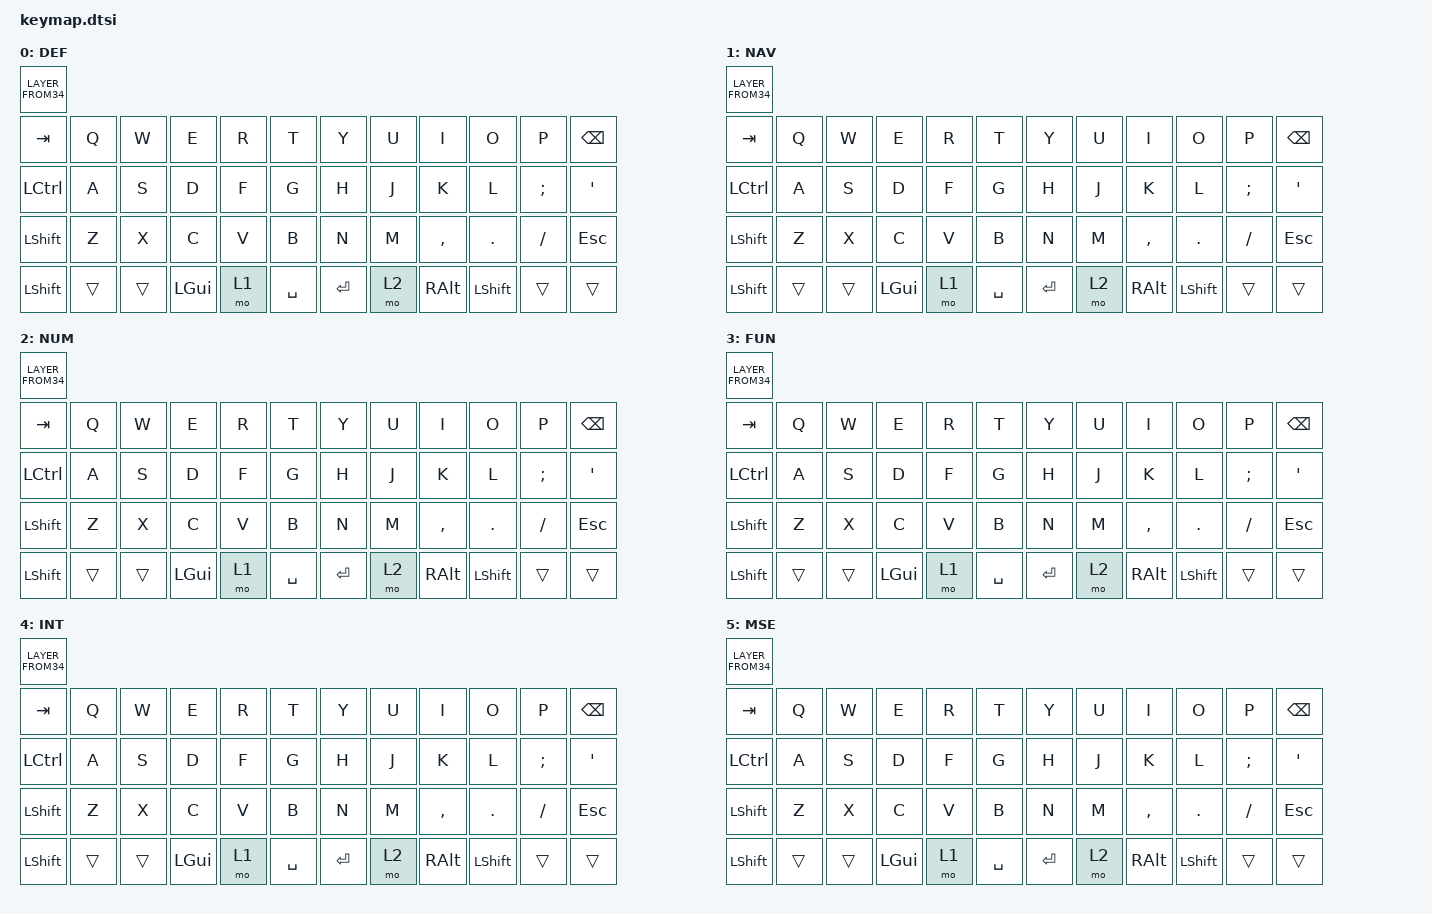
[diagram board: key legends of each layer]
/*
 * Copyright (c) 2020 The ZMK Contributors
 *
 * SPDX-License-Identifier: MIT
 */

#include <dt-bindings/zmk/bt.h>
#include <dt-bindings/zmk/keys.h>
#include <dt-bindings/zmk/mouse.h>
#include <dt-bindings/zmk/outputs.h>

#ifndef KEYMAP_DRAWER
#include "include/keys_de.h"
#endif

#define DEF 0
#define NAV 1
#define NUM 2
#define FUN 3
#define INT 4
#define MSE 5

#define CT(KEY) &mt LC(KEY) KEY

#define MEH     LC(LS(LALT))
#define HYPER   LC(LS(LA(LGUI)))

#define U_RDO   LC(DE_Y)
#define U_PST   LC(V)
#define U_PST_P LS(LC(V))
#define U_CPY   LC(C)
#define U_CUT   LC(X)
#define U_UND   LC(DE_Z)

#include "include/keypos.h"
#include "behaviors.dtsi"
#include "combos.dtsi"
#include "macros.dtsi"
#include "mouse.dtsi"

/ {
    conditional_layers {
        compatible = "zmk,conditional-layers";

        tri_layer  {
            if-layers = <NAV NUM>;
            then-layer = <FUN>;
        };
    };

    keymap {
        compatible = "zmk,keymap";

        default_layer {
            display-name = "DEF";
            bindings = <LAYER_FROM34( \
   &kp TAB    &kp Q  &kp W  &kp E     &kp R  &kp T        &kp Y    &kp U  &kp I      &kp O    &kp P     &kp BSPC
   &kp LCTRL  &kp A  &kp S  &kp D     &kp F  &kp G        &kp H    &kp J  &kp K      &kp L    &kp SEMI  &kp SQT
   &kp LSHFT  &kp Z  &kp X  &kp C     &kp V  &kp B        &kp N    &kp M  &kp COMMA  &kp DOT  &kp FSLH  &kp ESC
   &kp LSHFT  &trans    &trans &kp LGUI  &mo 1  &kp SPACE    &kp RET  &mo 2  &kp RALT  &kp LSHFT  &trans    &trans
            )>;
        };

        navigation_layer {
            display-name = "NAV";
            bindings = <LAYER_FROM34( \
   &kp TAB    &kp Q  &kp W  &kp E     &kp R  &kp T        &kp Y    &kp U  &kp I      &kp O    &kp P     &kp BSPC
   &kp LCTRL  &kp A  &kp S  &kp D     &kp F  &kp G        &kp H    &kp J  &kp K      &kp L    &kp SEMI  &kp SQT
   &kp LSHFT  &kp Z  &kp X  &kp C     &kp V  &kp B        &kp N    &kp M  &kp COMMA  &kp DOT  &kp FSLH  &kp ESC
   &kp LSHFT  &trans    &trans &kp LGUI  &mo 1  &kp SPACE    &kp RET  &mo 2  &kp RALT  &kp LSHFT  &trans    &trans
            )>;
        };

        number_layer {
            display-name = "NUM";
            bindings = <LAYER_FROM34( \
   &kp TAB    &kp Q  &kp W  &kp E     &kp R  &kp T        &kp Y    &kp U  &kp I      &kp O    &kp P     &kp BSPC
   &kp LCTRL  &kp A  &kp S  &kp D     &kp F  &kp G        &kp H    &kp J  &kp K      &kp L    &kp SEMI  &kp SQT
   &kp LSHFT  &kp Z  &kp X  &kp C     &kp V  &kp B        &kp N    &kp M  &kp COMMA  &kp DOT  &kp FSLH  &kp ESC
   &kp LSHFT  &trans    &trans &kp LGUI  &mo 1  &kp SPACE    &kp RET  &mo 2  &kp RALT  &kp LSHFT  &trans    &trans
            )>;
        };

        function_layer {
            display-name = "FUN";
            bindings = <LAYER_FROM34( \
   &kp TAB    &kp Q  &kp W  &kp E     &kp R  &kp T        &kp Y    &kp U  &kp I      &kp O    &kp P     &kp BSPC
   &kp LCTRL  &kp A  &kp S  &kp D     &kp F  &kp G        &kp H    &kp J  &kp K      &kp L    &kp SEMI  &kp SQT
   &kp LSHFT  &kp Z  &kp X  &kp C     &kp V  &kp B        &kp N    &kp M  &kp COMMA  &kp DOT  &kp FSLH  &kp ESC
   &kp LSHFT  &trans    &trans &kp LGUI  &mo 1  &kp SPACE    &kp RET  &mo 2  &kp RALT  &kp LSHFT  &trans    &trans
            )>;
        }; 

        international_layer {
            display-name = "INT";
            bindings = <LAYER_FROM34( \
   &kp TAB    &kp Q  &kp W  &kp E     &kp R  &kp T        &kp Y    &kp U  &kp I      &kp O    &kp P     &kp BSPC
   &kp LCTRL  &kp A  &kp S  &kp D     &kp F  &kp G        &kp H    &kp J  &kp K      &kp L    &kp SEMI  &kp SQT
   &kp LSHFT  &kp Z  &kp X  &kp C     &kp V  &kp B        &kp N    &kp M  &kp COMMA  &kp DOT  &kp FSLH  &kp ESC
   &kp LSHFT  &trans    &trans &kp LGUI  &mo 1  &kp SPACE    &kp RET  &mo 2  &kp RALT  &kp LSHFT  &trans    &trans
            )>;
        };

        mouse_layer {
            display-name = "MSE";
            bindings = <LAYER_FROM34( \
   &kp TAB    &kp Q  &kp W  &kp E     &kp R  &kp T        &kp Y    &kp U  &kp I      &kp O    &kp P     &kp BSPC
   &kp LCTRL  &kp A  &kp S  &kp D     &kp F  &kp G        &kp H    &kp J  &kp K      &kp L    &kp SEMI  &kp SQT
   &kp LSHFT  &kp Z  &kp X  &kp C     &kp V  &kp B        &kp N    &kp M  &kp COMMA  &kp DOT  &kp FSLH  &kp ESC
   &kp LSHFT  &trans    &trans &kp LGUI  &mo 1  &kp SPACE    &kp RET  &mo 2  &kp RALT  &kp LSHFT  &trans    &trans
            )>;
        };

        extra1 {
            status = "reserved";
        };

        extra2 {
            status = "reserved";
        };
    };
};
